# MC3_BFSW_ICONT register map
Vendor: Texas Instruments
Peripheral module from a debugger description file (folder TDA2Px).
Registers are 32-bit, access per field, reset 0x0 unless marked. A register's access mark holds for its fields unless they carry their own. Offsets are as the file gives them; lines under a group give offsets from that group; [hi:lo] are bit positions; {n}, {i} and the like mark numbered series; 'fields as' and 'values as' point back to an identical list; <NAME> marks a mode.

## MC3_BFSW_ICONT
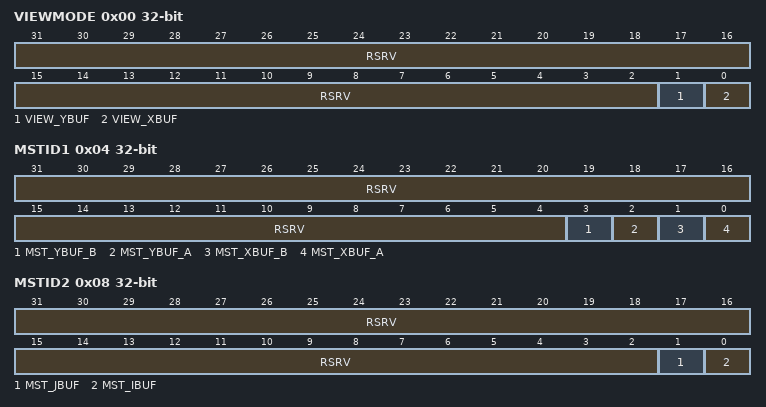
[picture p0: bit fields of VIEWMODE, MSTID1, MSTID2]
0x00 VIEWMODE — View mode register. It selects full-view mode or ping-pong view mode.
  [31:2] RSRV ro — Reserved. 0 is returned at read, and write is ignored.
  [1] VIEW_YBUF rw — View mode selection for Y buffer. 0: Full view mode is selected. 1: Ping-pong view mode is selected.
  [0] VIEW_XBUF rw — View mode selection for X buffer. 0: Full view mode is selected. 1: Ping-pong view mode is selected.
0x04 MSTID1 — Master ID 1 register Select master between HWA and DMA bus. This register is used in full-view and ping-pong view modes. This register is for buffers that have two physical memories. This register is affected by direct_switch_pi input port.
  [31:4] RSRV ro — Reserved. 0 is returned at read, and write is ignored.
  [3] MST_YBUF_B rw — Master selection for Y buffer B. This bit is used only in ping-pong view mode. 0: Buffer B is assigned to DMA. 1: Buffer B is assigned to HWA. This bit has no effect in full-view mode. If direct_switch_pi is high, the value of this bit is inverted.
  [2] MST_YBUF_A rw — Master selection for Y buffer A. This bit is used in full view and ping-pong view modes. In full-view mode: 0: Buffers A and B are assigned to DMA. 1: Buffers A and B are assigned to HWA. In ping-pong view mode: 0: Buffer A is assigned to DMA. 1: Buffer A is assigned to HWA. (Buffer B is not affected in ping-pong view mode.) If direct_switch_pi is high, the value of this bit is inverted.
  [1] MST_XBUF_B rw — Master selection for X buffer B. This bit is used only in ping-pong view mode. 0: Buffer B is assigned to DMA. 1: Buffer B is assigned to HWA. This bit has no effect in full-view mode. If direct_switch_pi is high, the value of this bit is inverted.
  [0] MST_XBUF_A rw — Master selection for X buffer A. This bit is used in full view and ping-pong view modes. In full-view mode: 0: Buffers A and B are assigned to DMA. 1: Buffers A and B are assigned to HWA. In ping-pong view mode: 0: Buffer A is assigned to DMA. 1: Buffer A is assigned to HWA. (Buffer B is not affected in ping-pong view mode.) If direct_switch_pi is high, the value of this bit is inverted.
0x08 MSTID2 ro — Master ID 1 register Select master between HWA and DMA bus. This register is for buffers that have only one physical memory. This register is not affected by direct_switch_pi input port.
  [31:2] RSRV — Reserved. 0 is returned at read, and write is ignored.
  [1] MST_JBUF — Master selection for J buffer. 0: Buffer is assigned to DMA. 1: Buffer is assigned to HWA.
  [0] MST_IBUF — Master selection for I buffer. 0: Buffer is assigned to DMA. 1: Buffer is assigned to HWA.
